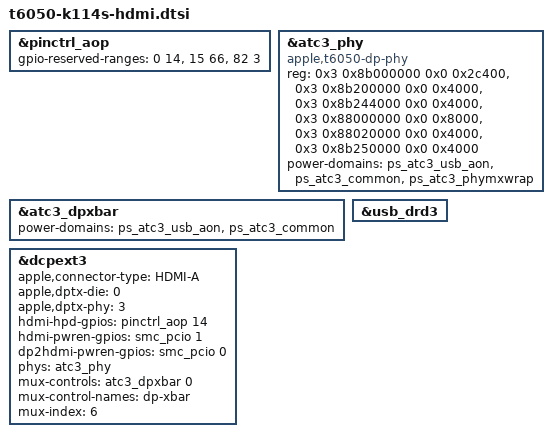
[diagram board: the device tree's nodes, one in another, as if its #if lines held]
// SPDX-License-Identifier: GPL-2.0+ OR MIT
/*
 * K114s (MacBook Pro 14-inch PROLED XDR, M5 Pro, Mac17,13): the HDMI port. DRAFT. NOT compiled
 * against a kernel tree, NOT booted on a K114s, NOT included by any tree of this repository
 * (issue #24, docs/hdmi-plan.md). It cannot do anything until the display hand-off works
 * (issues #2 and #17 and the D1-D9 trials): the HDMI output is a dcpext engine, and the boot
 * loader hands over dcpext engines only for a firmware image it pins.
 *
 * Port of betizzel/omarchy-m5 patches/j714s-27.2/linux/0017 (FatBoy721, "t6050-j714s: Describe
 * the HDMI port", tested on a J714s with macOS 27.3 firmware: 1920x1080@60, cold plug, hotplug).
 * Route: dcpext3 -> atc3 display crossbar -> ATC3 as a fixed four-lane DP PHY -> on-board
 * DP-to-HDMI converter. tests/k114s-adt-hdmi-facts.py reads this Mac's ADT and finds the same
 * values the J714s patch quotes (agent-run, 2026-11-15; 20 of 20 facts hold):
 *   atc3-dpphy        atc-dpphy,t602x, port-type 6, dfp endpoint 3, dfp port 0
 *   dp2hdmi-gpio0     hdmi_hpd = aop-gpio0 pin 14, force-dpfu = pin 15 (left undescribed)
 *                     hdmi_pwr_en = pKW8('pcIO', 0x800000, 0xf0000)
 *                     dp2hdmi_pwr_en = pKW8('pcIO', 0x0, 0x1a0000)
 *   dcpext3           ufp endpoint 3, port 0 -> crossbar state 2 * 3 + 0 = 6
 *   no usb-drd3 / ATC3 USB controller in the K114s ADT (the J714s has none either)
 *
 * Differences from the J714s file, each to be settled when the file is first compiled:
 *  - smc_pcio: the K114s list already carries both converter outputs (output 0 = dp2hdmi_pwr_en
 *    0x001a..., output 1 = hdmi_pwr_en 0x000f...800000, then gp1c, then the SD reader's; see the
 *    list in t6050-k114s-sd.dtsi), so no new list is written here; the indices are 0 (dp2hdmi) and 1 (hdmi),
 *    not the J714s's 2 and 1. This is read from our own files, not from a compiled tree.
 *  - pinctrl_aop: the J714s file frees AOP GPIO 14 because its base reserves 0-80. Whether the
 *    K114-K116 base does is unknown; the override below is the J714s one and must be checked.
 *  - The ATC3 node becomes "apple,t6050-dp-phy". That compatible, its six register windows and
 *    the dcpext3 properties (apple,connector-type, apple,dptx-die, hdmi-hpd-gpios, ...) exist
 *    only in betizzel's v272 series (kernel v272-11 and later; r3b is on v272-11, r3a is not).
 *  - The loader must fill the ATC tunables of a dp-phy node (aura patch 0011 of betizzel's
 *    set). The K114s ADT has them: atc-phy3 carries 21 tunable properties (agent-run).
 *  - The reg windows are J714s values; the ADT's atc-phy3 lists the same six addresses (agent-run). The labels
 *    usb_drd3, ps_atc3_usb_aon, ps_atc3_common and ps_atc3_phymxwrap are J714s names, unchecked until compile.
 *  - dcpext3 is taken away from the USB-C routes (it was dcpext2's pair for modes that need
 *    two pipelines).
 * Also needed, outside this file: patches 0018 (HDMI flips complete locally while the output
 * connects) and 0019 (forward converter IRQ_HPD service requests), both in the v272 series, and
 * for audio the DP audio work already in r3b.
 *
 * Nothing here is enabled unless the including tree defines K114S_R3B_HDMI. Include it after
 * t6050-k114s-common.dtsi, in a tree built on the r3b base.
 */
#ifdef K114S_R3B_HDMI

/* AOP GPIO 14 is the converter's HPD; pin 15 (force-dpfu) stays reserved, as on the J714s. */
&pinctrl_aop {
	gpio-reserved-ranges = <0 14>, <15 66>, <82 3>;
};

&atc3_phy {
	compatible = "apple,t6050-dp-phy";
	/* The fixed DP PHY needs the core window up to 0x2c400. */
	reg = <0x3 0x8b000000 0x0 0x2c400>,
	      <0x3 0x8b200000 0x0 0x4000>,
	      <0x3 0x8b244000 0x0 0x4000>,
	      <0x3 0x88000000 0x0 0x8000>,
	      <0x3 0x88020000 0x0 0x4000>,
	      <0x3 0x8b250000 0x0 0x4000>;
	reg-names = "core", "reset", "fabric", "axi2af", "lioa", "common-cfg";
	#phy-cells = <0>;
	/delete-property/ #reset-cells;
	/delete-property/ apple,guest-port-reserved;
	/delete-property/ mode-switch;
	/delete-property/ orientation-switch;
	/delete-property/ mboxes;
	power-domains = <&ps_atc3_usb_aon>, <&ps_atc3_common>, <&ps_atc3_phymxwrap>;
	power-domain-names = "usb-aon", "common", "wrapper";
	status = "okay";
};

/* Without Linux-managed domains the crossbar driver writes its select register with ATC3 off. */
&atc3_dpxbar {
	power-domains = <&ps_atc3_usb_aon>, <&ps_atc3_common>;
	power-domain-names = "usb-aon", "common";
	status = "okay";
};

&dcpext3 {
	apple,connector-type = "HDMI-A";
	apple,dptx-die = <0>;
	apple,dptx-phy = <3>;
	hdmi-hpd-gpios = <&pinctrl_aop 14 GPIO_ACTIVE_HIGH>;
	hdmi-pwren-gpios = <&smc_pcio 1 GPIO_ACTIVE_HIGH>;	/* K114s output 1; same index as the J714s */
	dp2hdmi-pwren-gpios = <&smc_pcio 0 GPIO_ACTIVE_HIGH>;	/* K114s output 0; the J714s has it at 2 */
	phys = <&atc3_phy>;
	phy-names = "dp-phy";
	mux-controls = <&atc3_dpxbar 0>;
	mux-control-names = "dp-xbar";
	/* 2 * dp-switch-ufp-endpoint (3) + port (0), as macOS's AppleT8142ATCDPXBAR */
	mux-index = <6>;
};

/* No usb-drd3 on this board: drop its links to the now DP-only PHY. */
&usb_drd3 {
	/delete-property/ phys;
	/delete-property/ phy-names;
	/delete-property/ resets;
};
#endif
